# ADuCM302x register map
Vendor: Analog Devices; Series: ADuCM302x; File version: 1p0
CPU: CM3 r0p1, little endian, no MPU, no FPU, 3 interrupt priority bits
Registers are 32-bit, read-write, reset 0x0 unless marked. A register's access mark holds for its fields unless they carry their own. Offsets are from the block's base; [hi:lo] are bit positions.

## FLCC0 — Flash Controller
Base 0x40018000
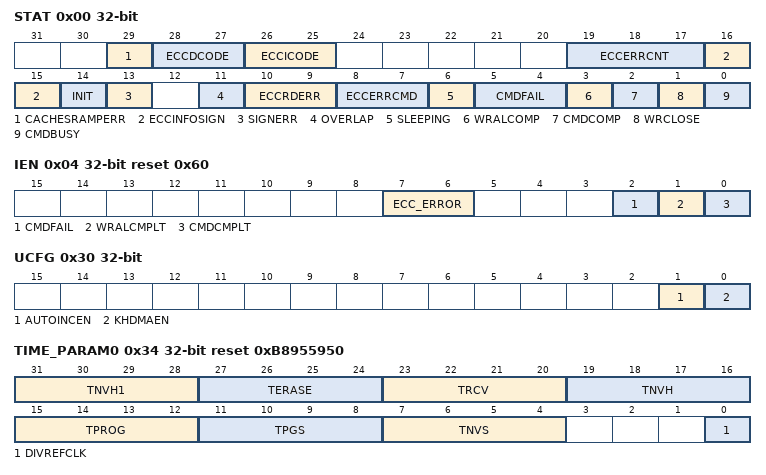
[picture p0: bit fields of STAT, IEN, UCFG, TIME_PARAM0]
0x00 STAT — Status
  [29] CACHESRAMPERR ro — SRAM Parity Errors in Cache Controller
  [28:27] ECCDCODE ro — DCode AHB Bus Error ECC Status
  [26:25] ECCICODE ro — ICode AHB Bus Error ECC Status
  [19:17] ECCERRCNT ro — ECC Correction Counter
  [16:15] ECCINFOSIGN ro — ECC Status of Flash Initialization
  [14] INIT ro — Flash Controller Initialization in Progress
  [13] SIGNERR ro — Signature Check Failure During Initialization
  [11] OVERLAP range 0x00000000..0x00000001 — Overlapping Command
  [10:9] ECCRDERR ro — ECC IRQ Cause
  [8:7] ECCERRCMD ro — ECC Errors Detected During User Issued SIGN Command
  [6] SLEEPING ro — Flash Array is in Low Power (Sleep) Mode
  [5:4] CMDFAIL ro — Provides Information on Command Failures
  [3] WRALCOMP ro — Write Almost Complete
  [2] CMDCOMP ro — Command Complete
  [1] WRCLOSE ro — WRITE Registers are Closed
  [0] CMDBUSY ro — Command Busy
0x04 IEN reset 0x60 — Interrupt Enable
  [7:6] ECC_ERROR — Control 2-bit ECC Error Events
    0=NONE_err (Do not generate a response to ECC events); 1=BUS_ERR_err (Generate Bus Errors in response to ECC events); 2=IRQ_err (Generate IRQs in response to ECC events)
  [2] CMDFAIL range 0x00000000..0x00000001 — Command Fail Interrupt Enable
  [1] WRALCMPLT range 0x00000000..0x00000001 — Write Almost Complete Interrupt Enable
  [0] CMDCMPLT range 0x00000000..0x00000001 — Command Complete Interrupt Enable
0x08 CMD — Command
  [3:0] VALUE — Commands
    0=IDLE; 1=ABORT; 2=SLEEP (Requests flash to enter Sleep mode); 3=SIGN; 4=WRITE; 5=BLANK_CHECK (Checks all of User Space; fails if any bits in user space are cleared); 6=ERASEPAGE; 7=MASSERASE
0x0C KH_ADDR — Write Address
  [18:3] VALUE range 0x00000000..0x0000FFFF — Key Hole Address
0x10 KH_DATA0 reset 0xFFFFFFFF — Write Lower Data
  [31:0] VALUE range 0x00000000..0xFFFFFFFF — Lower 32 Bits of Key Hole Data
0x14 KH_DATA1 reset 0xFFFFFFFF — Write Upper Data
  [31:0] VALUE range 0x00000000..0xFFFFFFFF — Upper Half of 64-bit Dualword Data to Be Written
0x18 PAGE_ADDR0 — Lower Page Address
  [18:10] VALUE range 0x00000000..0x000001FF — Lower Address Bits of the Page Address
0x1C PAGE_ADDR1 — Upper Page Address
  [18:10] VALUE range 0x00000000..0x000001FF — Upper Address Bits of the Page Address
0x20 KEY
  [31:0] VALUE wo — Key Register
0x24 WR_ABORT_ADDR — Write Abort Address
  [31:0] VALUE ro — Address Targeted by an Ongoing Write Command
0x28 WRPROT reset 0xFFFFFFFF — Write Protection
  [31:0] WORD range 0x00000000..0xFFFFFFFF — Write Protect
0x2C SIGNATURE
  [31:0] VALUE ro
0x30 UCFG — User Configuration
  [1] AUTOINCEN range 0x00000000..0x00000001 — Auto Address Increment for Key Hole Access
  [0] KHDMAEN range 0x00000000..0x00000001 — Key Hole DMA Enable
0x34 TIME_PARAM0 reset 0xB8955950 — Time Parameter 0
  [31:28] TNVH1 range 0x00000000..0x0000000F — NVSTR Hold Time During Mass Erase
  [27:24] TERASE range 0x00000000..0x0000000F — Erase Time
  [23:20] TRCV range 0x00000000..0x0000000F — Recovery Time
  [19:16] TNVH range 0x00000000..0x0000000F — NVSTR Hold Time
  [15:12] TPROG range 0x00000000..0x0000000F — Program Time
  [11:8] TPGS range 0x00000000..0x0000000F — NVSTR to Program Setup Time
  [7:4] TNVS range 0x00000000..0x0000000F — PROG/ERASE to NVSTR Setup Time
  [0] DIVREFCLK range 0x00000000..0x00000001 — Divide Reference Clock (by 2)
0x38 TIME_PARAM1 reset 0x4 — Time Parameter 1
  [3:0] TWK range 0x00000000..0x0000000F — Wakeup Time
0x3C ABORT_EN_LO — IRQ Abort Enable (Lower Bits)
  [31:0] VALUE range 0x00000000..0xFFFFFFFF — VALUE[31:0] Sys IRQ Abort Enable
0x40 ABORT_EN_HI — IRQ Abort Enable (Upper Bits)
  [31:0] VALUE range 0x00000000..0xFFFFFFFF — VALUE[63:32] Sys IRQ Abort Enable
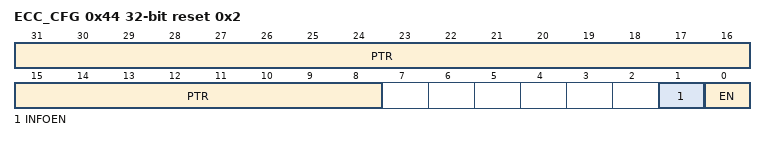
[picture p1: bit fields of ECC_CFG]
0x44 ECC_CFG reset 0x2 — ECC Configuration
  [31:8] PTR range 0x00000000..0x00FFFFFF — ECC Start Page Pointer
  [1] INFOEN range 0x00000000..0x00000001 — Info Space ECC Enable Bit
  [0] EN range 0x00000000..0x00000001 — ECC Enable
0x48 ECC_ADDR — ECC Status (Address)
  [18:0] VALUE ro — ECC Error Address
0x50 POR_SEC — Flash Security
  [0] SECURE range 0x00000000..0x00000001 — Prevent Read/Write Access to User Space (Sticky When Set)
0x54 VOL_CFG reset 0x1 — Volatile Flash Configuration
  [0] INFO_REMAP range 0x00000000..0x00000001 — Alias the Info Space to the Base Address of User Space
